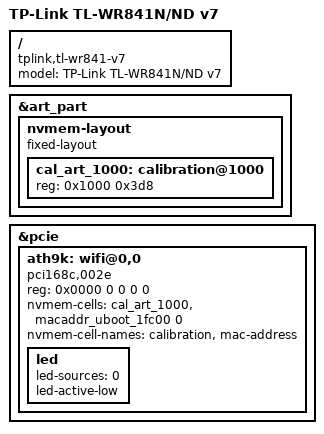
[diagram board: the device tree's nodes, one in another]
// SPDX-License-Identifier: GPL-2.0-or-later OR MIT

#include <dt-bindings/leds/common.h>

#include "ar7241_tplink.dtsi"

/ {
	compatible = "tplink,tl-wr841-v7", "qca,ar7241";
	model = "TP-Link TL-WR841N/ND v7";
};

&art_part {
	nvmem-layout {
		compatible = "fixed-layout";
		#address-cells = <1>;
		#size-cells = <1>;

		cal_art_1000: calibration@1000 {
			reg = <0x1000 0x3d8>;
		};
	};
};

&pcie {
	ath9k: wifi@0,0 {
		compatible = "pci168c,002e";
		reg = <0x0000 0 0 0 0>;
		nvmem-cells = <&cal_art_1000>, <&macaddr_uboot_1fc00 0>;
		nvmem-cell-names = "calibration", "mac-address";

		led {
			led-sources = <0>;
			led-active-low;
		};
	};
};
